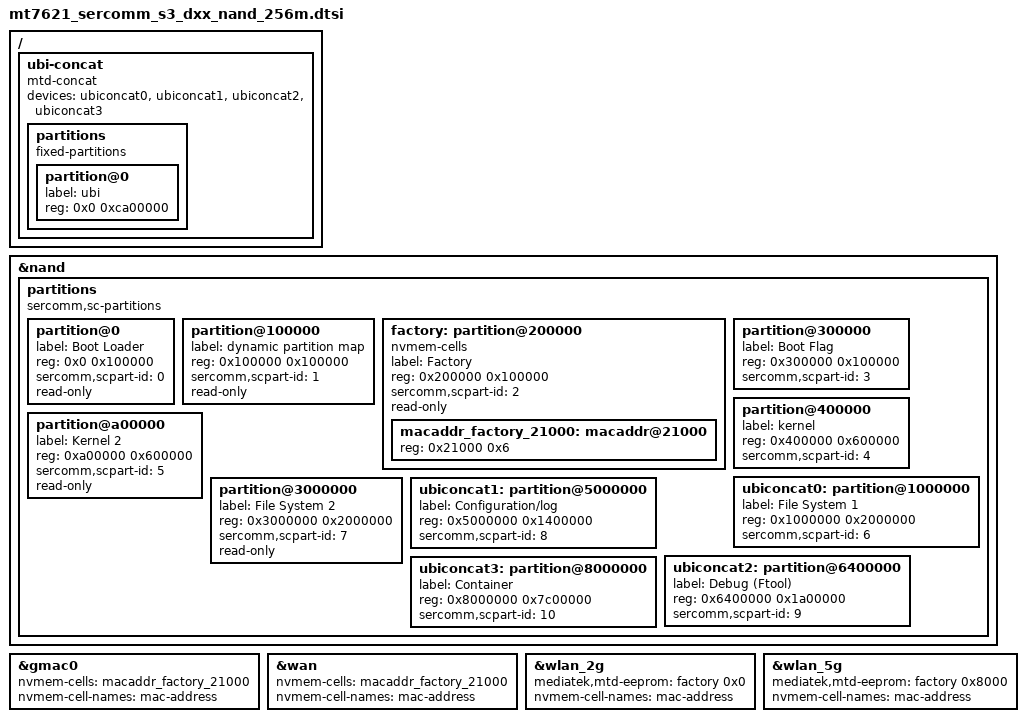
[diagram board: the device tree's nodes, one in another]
// SPDX-License-Identifier: GPL-2.0-or-later

#include "mt7621_sercomm_s3.dtsi"
// Sercomm S3 DF3 - Beeline SmartBox TURBO
// Sercomm S3 DKG - Rostelecom Sercomm RT-SF-1
/ {
	ubi-concat {
		compatible = "mtd-concat";
		devices = <&ubiconcat0 &ubiconcat1 &ubiconcat2 &ubiconcat3>;

		partitions {
			compatible = "fixed-partitions";
			#address-cells = <1>;
			#size-cells = <1>;

			partition@0 { // 206848 KiB = 202 MiB
				label = "ubi";
				reg = <0x0 0xca00000>;
			};
		};
	};
};

&nand {
	status = "okay";

	partitions {
		compatible = "sercomm,sc-partitions", "fixed-partitions";
		#address-cells = <1>;
		#size-cells = <1>;

		partition@0 {
			label = "Boot Loader";
			reg = <0x0 0x100000>;
			sercomm,scpart-id = <0>;
			read-only;
		};

		partition@100000 {
			label = "dynamic partition map";
			reg = <0x100000 0x100000>;
			sercomm,scpart-id = <1>;
			read-only;
		};

		factory: partition@200000 {
			label = "Factory";
			reg = <0x200000 0x100000>;
			sercomm,scpart-id = <2>;
			read-only;

			compatible = "nvmem-cells";
			#address-cells = <1>;
			#size-cells = <1>;

			macaddr_factory_21000: macaddr@21000 {
				reg = <0x21000 0x6>;
			};
		};

		partition@300000 {
			label = "Boot Flag";
			reg = <0x300000 0x100000>;
			sercomm,scpart-id = <3>;
		};

		partition@400000 {
			label = "kernel"; // Kernel 1
			reg = <0x400000 0x600000>;
			sercomm,scpart-id = <4>;
		};

		partition@a00000 {
			label = "Kernel 2";
			reg = <0xa00000 0x600000>;
			sercomm,scpart-id = <5>;
			read-only;
		};

		ubiconcat0: partition@1000000 {
			label = "File System 1";
			reg = <0x1000000 0x2000000>;
			sercomm,scpart-id = <6>;
		};

		partition@3000000 {
			label = "File System 2";
			reg = <0x3000000 0x2000000>;
			sercomm,scpart-id = <7>;
			read-only;
		};

		ubiconcat1: partition@5000000 {
			label = "Configuration/log";
			reg = <0x5000000 0x1400000>;
			sercomm,scpart-id = <8>;
		};

		ubiconcat2: partition@6400000 {
			label = "Debug (Ftool)";
			reg = <0x6400000 0x1a00000>;
			sercomm,scpart-id = <9>;
		};

		// Empty 0x7e00000-0x8000000 = 2 MiB

		ubiconcat3: partition@8000000 {
			label = "Container";
			reg = <0x8000000 0x7c00000>;
			sercomm,scpart-id = <10>;
		};

		/*
		 * 4 MiB Bad Block Table
		 * 0x10000000-0xfc00000=0x400000
		 */
	};
};

&gmac0 {
	nvmem-cells = <&macaddr_factory_21000>;
	nvmem-cell-names = "mac-address";
};

&wan {
	nvmem-cells = <&macaddr_factory_21000>;
	nvmem-cell-names = "mac-address";
};

&wlan_2g {
	mediatek,mtd-eeprom = <&factory 0x0>;
	nvmem-cell-names = "mac-address";
};

&wlan_5g {
	mediatek,mtd-eeprom = <&factory 0x8000>;
	nvmem-cell-names = "mac-address";
};
